# Port_U_Control_1 register map
Vendor: Texas Instruments
Peripheral module from a debugger description file (folder msp430).
Registers are 16-bit, read-write, reset 0x0 unless marked. A register's access mark holds for its fields unless they carry their own. Offsets are as the file gives them; lines under a group give offsets from that group; [hi:lo] are bit positions; {n}, {i} and the like mark numbered series; 'fields as' and 'values as' point back to an identical list; <NAME> marks a mode.

## Port_U_Control
0x900 LDOKEYPID access not given reset not defined — LDO Controller peripheral ID and key register
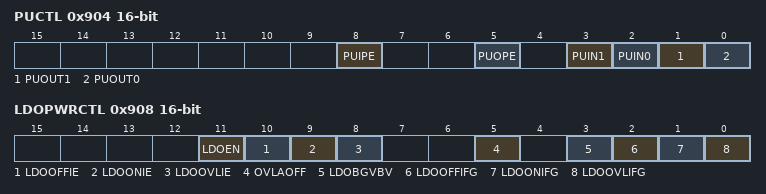
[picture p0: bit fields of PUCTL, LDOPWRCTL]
0x904 PUCTL — PU Control register
  [8] PUIPE — PU - PHY Single Ended Input enable
  [5] PUOPE — PU - Port Output Enable
  [3] PUIN1 — PU - PU1/DM Input Data
  [2] PUIN0 — PU - PU0/DP Input Data
  [1] PUOUT1 — PU - PU Output Signal Bit 1
  [0] PUOUT0 — PU - PU Output Signal Bit 0
0x908 LDOPWRCTL — LDO Power control register
  [11] LDOEN — PU - LDO Enable (3.3V)
  [10] LDOOFFIE — PU - LDOI "Going OFF" Interrupt Enable
  [9] LDOONIE — PU - LDOI "Coming ON" Interrupt Enable
  [8] LDOOVLIE — PU - Overload indication Interrupt Enable
  [5] OVLAOFF — PU - LDO overload auto off enable
  [3] LDOBGVBV — PU - LDO Bandgap and LDOI valid
  [2] LDOOFFIFG — PU - LDOI "Going OFF" Interrupt Flag
  [1] LDOONIFG — PU - LDOI "Coming ON" Interrupt Flag
  [0] LDOOVLIFG — PU - LDOO Overload Interrupt Flag
